# ESP32-C6-LP register map
Vendor: ESPRESSIF SYSTEMS (SHANGHAI) CO., LTD.; Series: ESP32 C-Series; File version: 3
CPU: RV32IMAC r0p0, little endian, no MPU, no FPU, 0 interrupt priority bits
Address unit: 32 bits
Registers are 32-bit, read-write, reset 0x0 unless marked. A register's access mark holds for its fields unless they carry their own. Offsets are from the block's base; [hi:lo] are bit positions; {n}, {i} and the like mark numbered series.

## LP_AON — LP_AON Peripheral
Base 0x600B1000
{0x0+4i} STORE{i} (i=0..9) — need_des
  [31:0] LP_AON_STORE{i}
0x28 GPIO_MUX — need_des
  [7:0] SEL
0x2C GPIO_HOLD0 — need_des
0x30 GPIO_HOLD1 — need_des
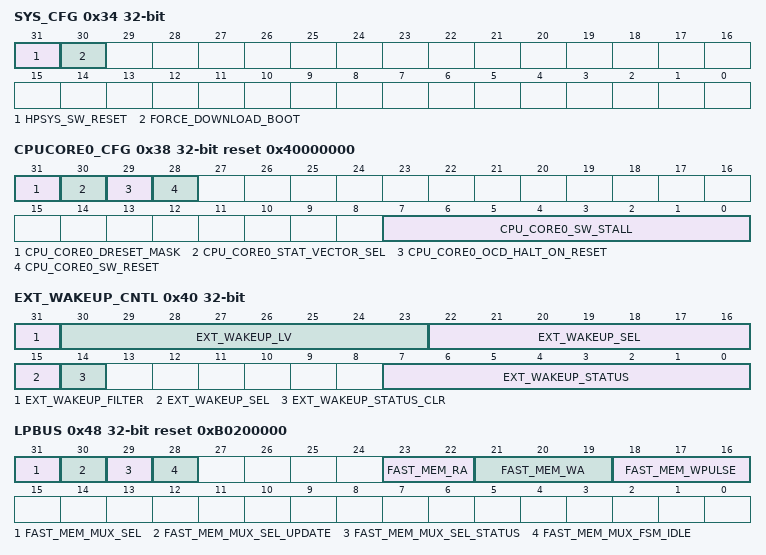
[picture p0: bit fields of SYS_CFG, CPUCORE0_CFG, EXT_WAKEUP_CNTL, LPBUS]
0x34 SYS_CFG access per field — need_des
  [31] HPSYS_SW_RESET wo — need_des
  [30] FORCE_DOWNLOAD_BOOT rw — need_des
0x38 CPUCORE0_CFG access per field reset 0x40000000 — need_des
  [31] CPU_CORE0_DRESET_MASK rw — need_des
  [30] CPU_CORE0_STAT_VECTOR_SEL rw — need_des
  [29] CPU_CORE0_OCD_HALT_ON_RESET rw — need_des
  [28] CPU_CORE0_SW_RESET wo — need_des
  [7:0] CPU_CORE0_SW_STALL rw — need_des
0x3C IO_MUX — need_des
  [31] RESET_DISABLE
0x40 EXT_WAKEUP_CNTL access per field — need_des
  [31] EXT_WAKEUP_FILTER rw — need_des
  [30:23] EXT_WAKEUP_LV rw — need_des
  [22:15] EXT_WAKEUP_SEL rw — need_des
  [14] EXT_WAKEUP_STATUS_CLR wo — need_des
  [7:0] EXT_WAKEUP_STATUS ro — need_des
0x44 USB — need_des
  [31] RESET_DISABLE
0x48 LPBUS access per field reset 0xB0200000 — need_des
  [31] FAST_MEM_MUX_SEL rw — need_des
  [30] FAST_MEM_MUX_SEL_UPDATE wo — need_des
  [29] FAST_MEM_MUX_SEL_STATUS ro — need_des
  [28] FAST_MEM_MUX_FSM_IDLE ro — need_des
  [23:22] FAST_MEM_RA rw — This field controls fast memory RA parameter.
  [21:19] FAST_MEM_WA rw — This field controls fast memory WA parameter.
  [18:16] FAST_MEM_WPULSE rw — This field controls fast memory WPULSE parameter.
0x4C SDIO_ACTIVE reset 0x2800000 — need_des
  [31:22] SDIO_ACT_DNUM
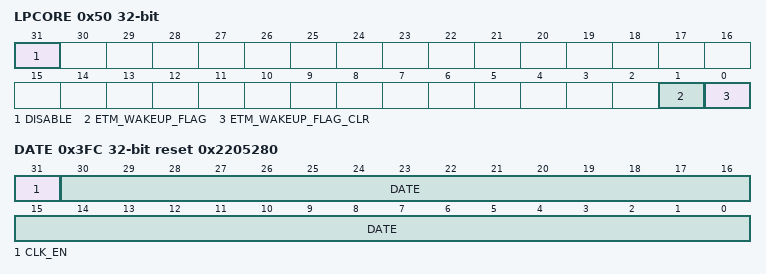
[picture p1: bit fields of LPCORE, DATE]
0x50 LPCORE access per field — need_des
  [31] DISABLE rw — need_des
  [1] ETM_WAKEUP_FLAG rw — need_des
  [0] ETM_WAKEUP_FLAG_CLR wo — need_des
0x54 SAR_CCT — need_des
  [31:29] SAR2_PWDET_CCT
0x3FC DATE reset 0x2205280 — need_des
  [31] CLK_EN — need_des
  [30:0] DATE — need_des

## LP_APM — Low-power Access Permission Management Controller
Base 0x600B3800
0x00 REGION_FILTER_EN reset 0x1 — Region filter enable register
  [3:0] REGION_FILTER_EN — Region filter enable
{0x4+0xC*i} REGION{i}_ADDR_START (i=0..3) — Region address register
  [31:0] REGION{i}_ADDR_START — Start address of region{i}
{0x8+0xC*i} REGION{i}_ADDR_END reset 0xFFFFFFFF (i=0..3) — Region address register
  [31:0] REGION{i}_ADDR_END — End address of region{i}
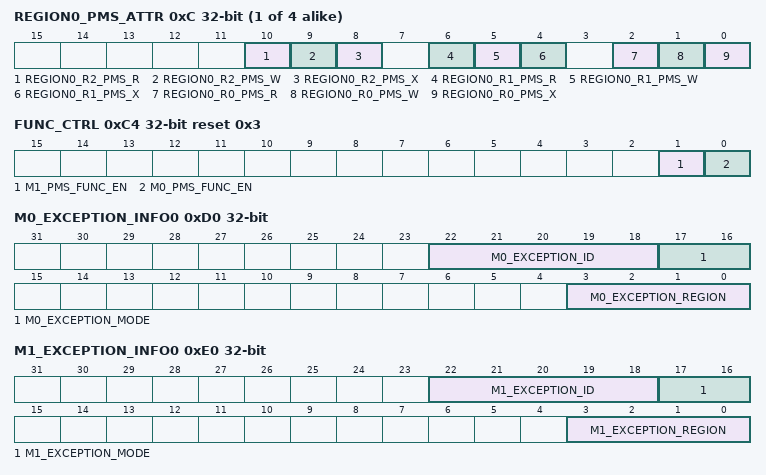
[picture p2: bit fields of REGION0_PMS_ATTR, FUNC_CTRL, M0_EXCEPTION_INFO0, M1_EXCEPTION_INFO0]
{0xC+0xC*i} REGION{i}_PMS_ATTR (i=0..3) — Region access authority attribute register
  [10] REGION{i}_R2_PMS_R — Region read authority in REE_MODE2
  [9] REGION{i}_R2_PMS_W — Region write authority in REE_MODE2
  [8] REGION{i}_R2_PMS_X — Region execute authority in REE_MODE2
  [6] REGION{i}_R1_PMS_R — Region read authority in REE_MODE1
  [5] REGION{i}_R1_PMS_W — Region write authority in REE_MODE1
  [4] REGION{i}_R1_PMS_X — Region execute authority in REE_MODE1
  [2] REGION{i}_R0_PMS_R — Region read authority in REE_MODE0
  [1] REGION{i}_R0_PMS_W — Region write authority in REE_MODE0
  [0] REGION{i}_R0_PMS_X — Region execute authority in REE_MODE0
0xC4 FUNC_CTRL reset 0x3 — PMS function control register
  [1] M1_PMS_FUNC_EN — PMS M1 function enable
  [0] M0_PMS_FUNC_EN — PMS M0 function enable
0xC8 M0_STATUS ro
  [1:0] M0_EXCEPTION_STATUS — Exception status
0xCC M0_STATUS_CLR wo — M0 status clear register
  [0] M0_REGION_STATUS_CLR — Clear exception status
0xD0 M0_EXCEPTION_INFO0 ro
  [22:18] M0_EXCEPTION_ID — Exception id information
  [17:16] M0_EXCEPTION_MODE — Exception mode
  [3:0] M0_EXCEPTION_REGION — Exception region
0xD4 M0_EXCEPTION_INFO1 ro
  [31:0] M0_EXCEPTION_ADDR — Exception addr
0xD8 M1_STATUS ro
  [1:0] M1_EXCEPTION_STATUS — Exception status
0xDC M1_STATUS_CLR wo — M1 status clear register
  [0] M1_REGION_STATUS_CLR — Clear exception status
0xE0 M1_EXCEPTION_INFO0 ro
  [22:18] M1_EXCEPTION_ID — Exception id information
  [17:16] M1_EXCEPTION_MODE — Exception mode
  [3:0] M1_EXCEPTION_REGION — Exception region
0xE4 M1_EXCEPTION_INFO1 ro
  [31:0] M1_EXCEPTION_ADDR — Exception addr
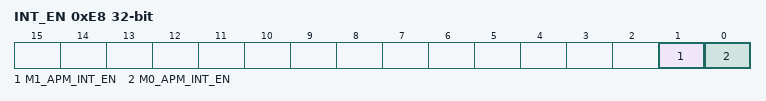
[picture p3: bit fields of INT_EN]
0xE8 INT_EN — APM interrupt enable register
  [1] M1_APM_INT_EN — APM M1 interrupt enable
  [0] M0_APM_INT_EN — APM M0 interrupt enable
0xEC CLOCK_GATE reset 0x1 — clock gating register
  [0] CLK_EN — reg_clk_en
0xFC DATE reset 0x2205240 — Version register
  [27:0] DATE — reg_date

## Notices in the file
Copyright 2025 Espressif Systems (Shanghai) PTE LTD
Licensed under the Apache License, Version 2.0 (the "License");
you may not use this file except in compliance with the License.
You may obtain a copy of the License at
http://www.apache.org/licenses/LICENSE-2.0
Unless required by applicable law or agreed to in writing, software
distributed under the License is distributed on an "AS IS" BASIS,
WITHOUT WARRANTIES OR CONDITIONS OF ANY KIND, either express or implied.
See the License for the specific language governing permissions and
limitations under the License.
